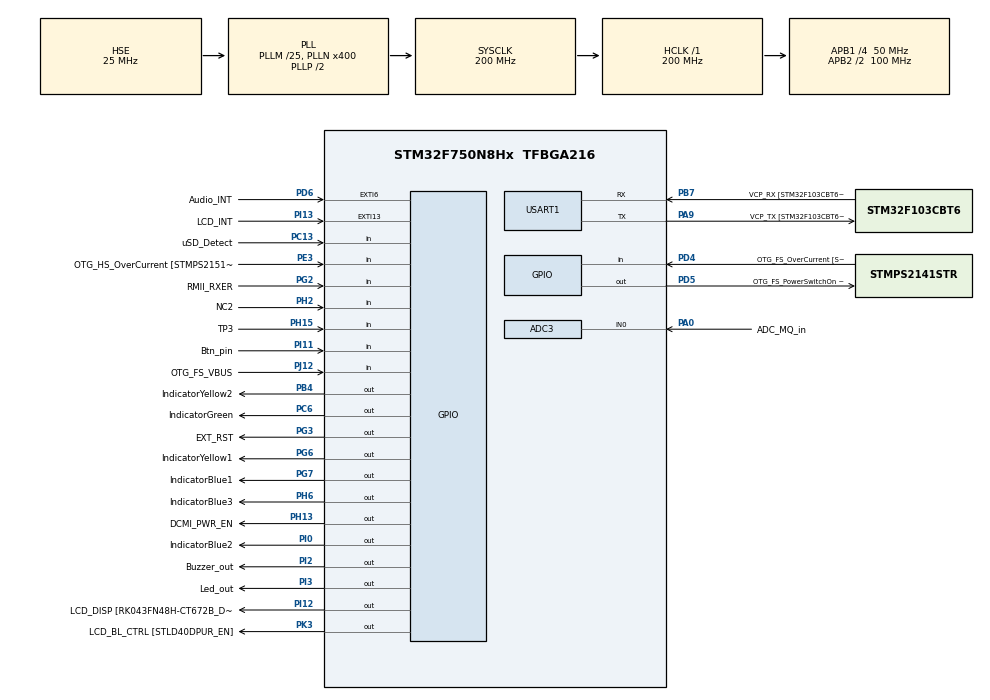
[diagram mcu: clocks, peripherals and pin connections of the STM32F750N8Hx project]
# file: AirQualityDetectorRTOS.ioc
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ADC3.Channel-0\#ChannelRegularConversion=ADC_CHANNEL_0
ADC3.Channel-IN0=ADC_CHANNEL_7
FREERTOS.Mutexes01=RegimeMutex,Dynamic,NULL;LED_Blink_Mutex,Dynamic,NULL;UARTMutex,Dynamic,NULL;LED_FSM_Mutex,Dynamic,NULL;ButtonCountMutex,Dynamic,NULL;SystemWorkStateMutex,Dynamic,NULL
FREERTOS.Tasks01=MainTask,24,1024,StartMainTask,Default,NULL,Dynamic,NULL,NULL;TerminalTask,24,1024,StartTerminalTask,Default,NULL,Dynamic,NULL,NULL;ButtonTask,24,512,StartButtonTask,Default,NULL,Dynamic,NULL,NULL;SingleLEDTask,24,512,StartSingleLEDTask,Default,NULL,Dynamic,NULL,NULL
FREERTOS.Timers01=ButtonTimer,ButtonTimerCallback,osTimerOnce,Default,NULL,Dynamic,NULL
FREERTOS.configTIMER_QUEUE_LENGTH=64
FREERTOS.configTIMER_TASK_PRIORITY=19
FREERTOS.configTIMER_TASK_STACK_DEPTH=1024
FREERTOS.configUSE_NEWLIB_REENTRANT=1
Mcu.Family=STM32F7
Mcu.Name=STM32F750N8Hx
Mcu.Package=TFBGA216
NVIC.PriorityGroup=NVIC_PRIORITYGROUP_4
NVIC.TIM8_TRG_COM_TIM14_IRQn=true\:15\:0\:false\:false\:true\:false\:false\:true\:true
NVIC.TimeBase=TIM8_TRG_COM_TIM14_IRQn
NVIC.TimeBaseIP=TIM14
NVIC.USART1_IRQn=true\:5\:0\:false\:false\:true\:true\:true\:true\:true
PA0/WKUP.GPIO_Label=ADC_MQ_in
PA0/WKUP.GPIO_Mode=GPIO_MODE_ANALOG
PA0/WKUP.GPIO_PuPd=GPIO_NOPULL
PA0/WKUP.Signal=ADCx_IN0
PA1.GPIO_Label=RMII_REF_CLK [LAN8742A-CZ-TR_REFCLK0]
PA1.Signal=ETH_REF_CLK
PA10.GPIO_Label=OTG_FS_ID
PA10.Signal=USB_OTG_FS_ID
PA11.GPIO_Label=OTG_FS_N
PA11.Signal=USB_OTG_FS_DM
PA12.GPIO_Label=OTG_FS_P
PA12.Signal=USB_OTG_FS_DP
PA13.GPIO_Label=SWDIO
PA13.Mode=Serial_Wire
PA13.Signal=SYS_JTMS-SWDIO
PA14.GPIO_Label=SWCLK
PA14.Mode=Serial_Wire
PA14.Signal=SYS_JTCK-SWCLK
PA15.GPIO_Label=ARDUINO PWM/D9
PA15.GPIO_ModeDefaultPP=GPIO_MODE_AF_PP
PA15.GPIO_PuPd=GPIO_NOPULL
PA15.GPIO_Speed=GPIO_SPEED_FREQ_LOW
PA15.Signal=S_TIM2_CH1_ETR
PA2.GPIO_Label=RMII_MDIO [LAN8742A-CZ-TR_MDIO]
PA2.Signal=ETH_MDIO
PA4.GPIO_Label=DCMI_HSYNC
PA4.Signal=DCMI_HSYNC
PA6.Signal=DCMI_PIXCLK
PA7.GPIO_Label=RMII_CRS_DV [LAN8742A-CZ-TR_CRS_DV]
PA7.Signal=ETH_CRS_DV
PA8.GPIO_Label=ARDUINO PWM/D10
PA8.GPIO_ModeDefaultPP=GPIO_MODE_AF_PP
PA8.GPIO_PuPd=GPIO_NOPULL
PA8.GPIO_Speed=GPIO_SPEED_FREQ_LOW
PA8.Signal=S_TIM1_CH1
PA9.GPIO_Label=VCP_TX [STM32F103CBT6_PA3]
PA9.GPIO_PuPd=GPIO_NOPULL
PA9.GPIO_Speed=GPIO_SPEED_FREQ_LOW
PA9.Mode=Asynchronous
PA9.Signal=USART1_TX
PB10.GPIO_Label=ULPI_D3 [USB3320C-EZK_D3]
PB10.Signal=USB_OTG_HS_ULPI_D3
PB14.GPIO_Label=ARDUINO MISO/D12
PB14.GPIO_Mode=GPIO_MODE_AF_PP
PB14.GPIO_PuPd=GPIO_NOPULL
PB14.GPIO_Speed=GPIO_SPEED_FREQ_LOW
PB14.Signal=SPI2_MISO
PB15.GPIO_Label=ARDUINO MOSI/PWM/D11
PB15.GPIO_Mode=GPIO_MODE_AF_PP
PB15.GPIO_PuPd=GPIO_NOPULL
PB15.GPIO_Speed=GPIO_SPEED_FREQ_LOW
PB15.Signal=SPI2_MOSI
PB2.Signal=QUADSPI_CLK
PB3.GPIO_Label=SWO
PB3.Signal=SYS_JTDO-SWO
PB4.GPIO_Label=IndicatorYellow2
PB4.GPIO_PuPd=GPIO_PULLDOWN
PB4.Signal=GPIO_Output
PB6.GPIO_Label=QSPI_NCS [N25Q128A13EF840E_S]
PB6.Signal=QUADSPI_BK1_NCS
PB7.GPIO_Label=VCP_RX [STM32F103CBT6_PA2]
PB7.GPIO_PuPd=GPIO_NOPULL
PB7.GPIO_Speed=GPIO_SPEED_FREQ_LOW
PB7.Mode=Asynchronous
PB7.Signal=USART1_RX
PB8.GPIO_Label=ARDUINO SCL/D15
PB8.GPIO_Mode=GPIO_MODE_AF_OD
PB8.GPIO_Pu=GPIO_PULLUP
PB8.GPIO_Speed=GPIO_SPEED_FREQ_LOW
PB8.Signal=I2C1_SCL
PB9.GPIO_Label=ARDUINO SDA/D14
PB9.GPIO_Mode=GPIO_MODE_AF_OD
PB9.GPIO_Pu=GPIO_PULLUP
PB9.GPIO_Speed=GPIO_SPEED_FREQ_LOW
PB9.Signal=I2C1_SDA
PC1.GPIO_Label=RMII_MDC [LAN8742A-CZ-TR_MDC]
PC1.Signal=ETH_MDC
PC10.GPIO_Label=SDMMC_D2
PC10.Signal=SDMMC1_D2
PC11.GPIO_Label=SDMMC_D3
PC11.Signal=SDMMC1_D3
PC12.GPIO_Label=SDMMC_CK
PC12.Signal=SDMMC1_CK
PC13.GPIO_Label=uSD_Detect
PC13.Signal=GPIO_Input
PC14/OSC32_IN.GPIO_Label=RCC_OSC32_IN
PC14/OSC32_IN.Mode=LSE-External-Oscillator
PC14/OSC32_IN.Signal=RCC_OSC32_IN
PC15/OSC32_OUT.GPIO_Label=RCC_OSC32_OUT
PC15/OSC32_OUT.Mode=LSE-External-Oscillator
PC15/OSC32_OUT.Signal=RCC_OSC32_OUT
PC3.GPIO_Label=FMC_SDCKE0 [MT48LC4M32B2B5-6A_CKE]
PC3.Signal=FMC_SDCKE0
PC4.GPIO_Label=RMII_RXD0 [LAN8742A-CZ-TR_RXD0]
PC4.Signal=ETH_RXD0
PC5.GPIO_Label=RMII_RXD1 [LAN8742A-CZ-TR_RXD1]
PC5.Signal=ETH_RXD1
PC6.GPIO_Label=IndicatorGreen
PC6.GPIO_PuPd=GPIO_PULLDOWN
PC6.Signal=GPIO_Output
PC7.GPIO_Label=ARDUINO RX/D0
PC7.Signal=USART6_RX
PC8.Signal=SDMMC1_D0
PC9.Signal=SDMMC1_D1
PD0.GPIO_Label=FMC_D2 [MT48LC4M32B2B5-6A_DQ2]
PD0.Signal=FMC_D2_DA2
PD1.GPIO_Label=FMC_D3 [MT48LC4M32B2B5-6A_DQ3]
PD1.Signal=FMC_D3_DA3
PD10.GPIO_Label=FMC_D15 [MT48LC4M32B2B5-6A_DQ15]
PD10.Signal=FMC_D15_DA15
PD11.GPIO_Label=QSPI_D0 [N25Q128A13EF840E_DQ0]
PD11.Signal=QUADSPI_BK1_IO0
PD12.GPIO_Label=QSPI_D1 [N25Q128A13EF840E_DQ1]
PD12.Signal=QUADSPI_BK1_IO1
PD13.GPIO_Label=QSPI_D3 [N25Q128A13EF840E_DQ3]
PD13.Signal=QUADSPI_BK1_IO3
PD14.GPIO_Label=FMC_D0 [MT48LC4M32B2B5-6A_DQ0]
PD14.Signal=FMC_D0_DA0
PD15.GPIO_Label=FMC_D1 [MT48LC4M32B2B5-6A_DQ1]
PD15.Signal=FMC_D1_DA1
PD2.GPIO_Label=SDMMC_CMD
PD2.Signal=SDMMC1_CMD
PD3.GPIO_Label=DCMI_D5
PD3.Signal=DCMI_D5
PD4.GPIO_Label=OTG_FS_OverCurrent [STMPS2141STR_Fault]
PD4.Signal=GPIO_Input
PD5.GPIO_Label=OTG_FS_PowerSwitchOn [STMPS2141STR_EN]
PD5.PinState=GPIO_PIN_SET
PD5.Signal=GPIO_Output
PD6.GPIO_Label=Audio_INT
PD6.GPIO_ModeDefaultEXTI=GPIO_MODE_EVT_RISING
PD6.Signal=GPXTI6
PD7.GPIO_Label=SPDIF_RX0 [74LVC1G04SE_4]
PD7.Signal=SPDIFRX_IN0
PD8.GPIO_Label=FMC_D13 [MT48LC4M32B2B5-6A_DQ13]
PD8.Signal=FMC_D13_DA13
PD9.GPIO_Label=FMC_D14 [MT48LC4M32B2B5-6A_DQ14]
PD9.Signal=FMC_D14_DA14
PE0.GPIO_Label=FMC_NBL0 [MT48LC4M32B2B5-6A_DQM0]
PE0.Signal=FMC_NBL0
PE1.GPIO_Label=FMC_NBL1 [MT48LC4M32B2B5-6A_DQM1]
PE1.Signal=FMC_NBL1
PE10.GPIO_Label=FMC_D7 [MT48LC4M32B2B5-6A_DQ7]
PE10.Signal=FMC_D7_DA7
PE11.GPIO_Label=FMC_D8 [MT48LC4M32B2B5-6A_DQ8]
PE11.Signal=FMC_D8_DA8
PE12.GPIO_Label=FMC_D9 [MT48LC4M32B2B5-6A_DQ9]
PE12.Signal=FMC_D9_DA9
PE13.GPIO_Label=FMC_D10 [MT48LC4M32B2B5-6A_DQ10]
PE13.Signal=FMC_D10_DA10
PE14.GPIO_Label=FMC_D11 [MT48LC4M32B2B5-6A_DQ11]
PE14.Signal=FMC_D11_DA11
PE15.GPIO_Label=FMC_D12 [MT48LC4M32B2B5-6A_DQ12]
PE15.Signal=FMC_D12_DA12
PE2.GPIO_Label=QSPI_D2 [N25Q128A13EF840E_DQ2]
PE2.Signal=QUADSPI_BK1_IO2
PE3.GPIO_Label=OTG_HS_OverCurrent [STMPS2151STR_FAULT]
PE3.Signal=GPIO_Input
PE4.GPIO_Label=LCD_B0 [RK043FN48H-CT672B_B0]
PE4.Signal=LTDC_B0
PE5.GPIO_Label=DCMI_D6
PE5.Signal=DCMI_D6
PE6.GPIO_Label=DCMI_D7
PE6.Signal=DCMI_D7
PE7.GPIO_Label=FMC_D4 [MT48LC4M32B2B5-6A_DQ4]
PE7.Signal=FMC_D4_DA4
PE8.GPIO_Label=FMC_D5 [MT48LC4M32B2B5-6A_DQ5]
PE8.Signal=FMC_D5_DA5
PE9.GPIO_Label=FMC_D6 [MT48LC4M32B2B5-6A_DQ6]
PE9.Signal=FMC_D6_DA6
PF0.GPIO_Label=FMC_A0 [MT48LC4M32B2B5-6A_A0]
PF0.Signal=FMC_A0
PF1.GPIO_Label=FMC_A1 [MT48LC4M32B2B5-6A_A1]
PF1.Signal=FMC_A1
PF10.GPIO_Label=ARDUINO A1
PF10.GPIO_Mode=GPIO_MODE_ANALOG
PF10.GPIO_PuPd=GPIO_NOPULL
PF10.Signal=ADC3_IN8
PF11.GPIO_Label=FMC_SDNRAS [MT48LC4M32B2B5-6A_RAS]
PF11.Signal=FMC_SDNRAS
PF12.GPIO_Label=FMC_A6 [MT48LC4M32B2B5-6A_A6]
PF12.Signal=FMC_A6
PF13.GPIO_Label=FMC_A7 [MT48LC4M32B2B5-6A_A7]
PF13.Signal=FMC_A7
PF14.GPIO_Label=FMC_A8 [MT48LC4M32B2B5-6A_A8]
PF14.Signal=FMC_A8
PF15.GPIO_Label=FMC_A9 [MT48LC4M32B2B5-6A_A9]
PF15.Signal=FMC_A9
PF2.GPIO_Label=FMC_A2 [MT48LC4M32B2B5-6A_A2]
PF2.Signal=FMC_A2
PF3.GPIO_Label=FMC_A3 [MT48LC4M32B2B5-6A_A3]
PF3.Signal=FMC_A3
PF4.GPIO_Label=FMC_A4 [MT48LC4M32B2B5-6A_A4]
PF4.Signal=FMC_A4
PF5.GPIO_Label=FMC_A5 [MT48LC4M32B2B5-6A_A5]
PF5.Signal=FMC_A5
PF6.GPIO_Label=ARDUINO A5
PF6.GPIO_Mode=GPIO_MODE_ANALOG
PF6.GPIO_PuPd=GPIO_NOPULL
PF6.Signal=ADC3_IN4
PF7.GPIO_Label=ARDUINO A4
PF7.GPIO_Mode=GPIO_MODE_ANALOG
PF7.GPIO_PuPd=GPIO_NOPULL
PF7.Signal=ADC3_IN5
PF8.GPIO_Label=ARDUINO A3
PF8.GPIO_Mode=GPIO_MODE_ANALOG
PF8.GPIO_PuPd=GPIO_NOPULL
PF8.Signal=ADC3_IN6
PF9.GPIO_Label=ARDUINO A2
PF9.GPIO_Mode=GPIO_MODE_ANALOG
PF9.GPIO_PuPd=GPIO_NOPULL
PF9.Signal=ADC3_IN7
PG0.GPIO_Label=FMC_A10 [MT48LC4M32B2B5-6A_A10]
PG0.Signal=FMC_A10
PG1.GPIO_Label=FMC_A11 [MT48LC4M32B2B5-6A_A11]
PG1.Signal=FMC_A11
PG10.GPIO_Label=SAI2_SDB [WM8994ECS/R_ADCDAT1]
PG10.Signal=SAI2_SD_B
PG11.GPIO_Label=RMII_TX_EN [LAN8742A-CZ-TR_TXEN]
PG11.Signal=ETH_TX_EN
PG12.GPIO_Label=LCD_B4 [RK043FN48H-CT672B_B4]
PG12.Signal=LTDC_B4
PG13.GPIO_Label=RMII_TXD0 [LAN8742A-CZ-TR_TXD0]
PG13.Signal=ETH_TXD0
PG14.GPIO_Label=RMII_TXD1 [LAN8742A-CZ-TR_TXD1]
PG14.Signal=ETH_TXD1
PG15.GPIO_Label=FMC_SDNCAS [MT48LC4M32B2B5-6A_CAS]
PG15.Signal=FMC_SDNCAS
PG2.GPIO_Label=RMII_RXER
PG2.Signal=GPIO_Input
PG3.GPIO_Label=EXT_RST
PG3.Signal=GPIO_Output
PG4.GPIO_Label=FMC_BA0 [MT48LC4M32B2B5-6A_BA0]
PG4.Signal=FMC_A14_BA0
PG5.GPIO_Label=FMC_BA1 [MT48LC4M32B2B5-6A_BA1]
PG5.Signal=FMC_A15_BA1
PG6.GPIO_Label=IndicatorYellow1
PG6.GPIO_PuPd=GPIO_PULLDOWN
PG6.Signal=GPIO_Output
PG7.GPIO_Label=IndicatorBlue1
PG7.GPIO_PuPd=GPIO_PULLDOWN
PG7.Signal=GPIO_Output
PG8.GPIO_Label=FMC_SDCLK [MT48LC4M32B2B5-6A_CLK]
PG8.Signal=FMC_SDCLK
PG9.GPIO_Label=DCMI_VSYNC
PG9.Signal=DCMI_VSYNC
PH0/OSC_IN.GPIO_Label=OSC_25M [NZ2520SB-25.00M_OUT]
PH0/OSC_IN.Mode=HSE-External-Oscillator
PH0/OSC_IN.Signal=RCC_OSC_IN
PH1/OSC_OUT.Mode=HSE-External-Oscillator
PH1/OSC_OUT.Signal=RCC_OSC_OUT
PH10.GPIO_Label=DCMI_D1
PH10.Signal=DCMI_D1
PH11.GPIO_Label=DCMI_D2
PH11.Signal=DCMI_D2
PH12.GPIO_Label=DCMI_D3
PH12.Signal=DCMI_D3
PH13.GPIO_Label=DCMI_PWR_EN
PH13.Signal=GPIO_Output
PH14.GPIO_Label=DCMI_D4
PH14.Signal=DCMI_D4
PH15.GPIO_Label=TP3
PH15.Signal=GPIO_Input
PH2.GPIO_Label=NC2
PH2.Signal=GPIO_Input
PH3.GPIO_Label=FMC_SDNE0 [MT48LC4M32B2B5-6A_CS]
PH3.Signal=FMC_SDNE0
PH5.GPIO_Label=FMC_SDNME [MT48LC4M32B2B5-6A_WE]
PH5.Signal=FMC_SDNWE
PH6.GPIO_Label=IndicatorBlue3
PH6.GPIO_PuPd=GPIO_PULLDOWN
PH6.Signal=GPIO_Output
PH7.GPIO_Label=LCD_SCL [RK043FN48H-CT672B_SCL]
PH7.GPIO_Pu=GPIO_PULLUP
PH7.Signal=I2C3_SCL
PH8.GPIO_Label=LCD_SDA [RK043FN48H-CT672B_SDA]
PH8.GPIO_Pu=GPIO_PULLUP
PH8.Signal=I2C3_SDA
PH9.GPIO_Label=DCMI_D0
PH9.Signal=DCMI_D0
PI0.GPIO_Label=IndicatorBlue2
PI0.GPIO_PuPd=GPIO_PULLDOWN
PI0.Signal=GPIO_Output
PI1.GPIO_Label=ARDUINO SCK/D13
PI1.GPIO_Mode=GPIO_MODE_AF_PP
PI1.GPIO_PuPd=GPIO_NOPULL
PI1.GPIO_Speed=GPIO_SPEED_FREQ_LOW
PI1.Signal=SPI2_SCK
PI10.GPIO_Label=LCD_HSYNC [RK043FN48H-CT672B_HSYNC]
PI10.Signal=LTDC_HSYNC
PI11.GPIO_Label=Btn_pin
PI11.GPIO_PuPd=GPIO_PULLDOWN
PI11.Signal=GPIO_Input
PI12.GPIO_Label=LCD_DISP [RK043FN48H-CT672B_DISP] 
PI12.PinState=GPIO_PIN_SET
PI12.Signal=GPIO_Output
PI13.GPIO_Label=LCD_INT
PI13.GPIO_ModeDefaultEXTI=GPIO_MODE_EVT_RISING
PI13.Signal=GPXTI13
PI14.GPIO_Label=LCD_CLK [RK043FN48H-CT672B_CLK]
PI14.Signal=LTDC_CLK
PI15.GPIO_Label=LCD_R0 [RK043FN48H-CT672B_R0]
PI15.Signal=LTDC_R0
PI2.GPIO_Label=Buzzer_out
PI2.GPIO_PuPd=GPIO_PULLDOWN
PI2.Signal=GPIO_Output
PI3.GPIO_Label=Led_out
PI3.GPIO_PuPd=GPIO_PULLDOWN
PI3.Signal=GPIO_Output
PI4.GPIO_Label=SAI2_MCLKA [WM8994ECS/R_MCLK1]
PI4.Signal=SAI2_MCLK_A
PI5.GPIO_Label=SAI2_SCKA [WM8994ECS/R_BCLK1]
PI5.Signal=SAI2_SCK_A
PI6.GPIO_Label=SAI2_SDA [WM8994ECS/R_DACDAT1]
PI6.Signal=SAI2_SD_A
PI7.GPIO_Label=SAI2_FSA [WM8994ECS/R_LRCLK1]
PI7.Signal=SAI2_FS_A
PI8.GPIO_Label=NC1 [TP2]
PI8.Signal=RTC_TS
PI9.GPIO_Label=LCD_VSYNC [RK043FN48H-CT672B_VSYNC]
PI9.Signal=LTDC_VSYNC
PJ0.GPIO_Label=LCD_R1 [RK043FN48H-CT672B_R1]
PJ0.Signal=LTDC_R1
PJ1.GPIO_Label=LCD_R2 [RK043FN48H-CT672B_R2]
PJ1.Signal=LTDC_R2
PJ10.GPIO_Label=LCD_G3 [RK043FN48H-CT672B_G3]
PJ10.Signal=LTDC_G3
PJ11.GPIO_Label=LCD_G4 [RK043FN48H-CT672B_G4]
PJ11.Signal=LTDC_G4
PJ12.GPIO_Label=OTG_FS_VBUS
PJ12.Signal=GPIO_Input
PJ13.GPIO_Label=LCD_B1 [RK043FN48H-CT672B_B1]
PJ13.Signal=LTDC_B1
PJ14.GPIO_Label=LCD_B2 [RK043FN48H-CT672B_B2]
PJ14.Signal=LTDC_B2
PJ15.GPIO_Label=LCD_B3 [RK043FN48H-CT672B_B3]
PJ15.Signal=LTDC_B3
PJ2.GPIO_Label=LCD_R3 [RK043FN48H-CT672B_R3]
PJ2.Signal=LTDC_R3
PJ3.GPIO_Label=LCD_R4 [RK043FN48H-CT672B_R4]
PJ3.Signal=LTDC_R4
PJ4.GPIO_Label=LCD_R5 [RK043FN48H-CT672B_R5]
PJ4.Signal=LTDC_R5
PJ5.GPIO_Label=LCD_R6 [RK043FN48H-CT672B_R6]
PJ5.Signal=LTDC_R6
PJ6.GPIO_Label=LCD_R7 [RK043FN48H-CT672B_R7]
PJ6.Signal=LTDC_R7
PJ7.GPIO_Label=LCD_G0 [RK043FN48H-CT672B_G0]
PJ7.Signal=LTDC_G0
PJ8.GPIO_Label=LCD_G1 [RK043FN48H-CT672B_G1]
PJ8.Signal=LTDC_G1
PJ9.GPIO_Label=LCD_G2 [RK043FN48H-CT672B_G2]
PJ9.Signal=LTDC_G2
PK0.GPIO_Label=LCD_G5 [RK043FN48H-CT672B_G5]
PK0.Signal=LTDC_G5
PK1.GPIO_Label=LCD_G6 [RK043FN48H-CT672B_G6]
PK1.Signal=LTDC_G6
PK2.GPIO_Label=LCD_G7 [RK043FN48H-CT672B_G7]
PK2.Signal=LTDC_G7
PK3.GPIO_Label=LCD_BL_CTRL [STLD40DPUR_EN]
PK3.GPIO_Speed=GPIO_SPEED_FREQ_LOW
PK3.PinState=GPIO_PIN_SET
PK3.Signal=GPIO_Output
PK4.GPIO_Label=LCD_B5 [RK043FN48H-CT672B_B5]
PK4.Signal=LTDC_B5
PK5.GPIO_Label=LCD_B6 [RK043FN48H-CT672B_B6]
PK5.Signal=LTDC_B6
PK6.GPIO_Label=LCD_B7 [RK043FN48H-CT672B_B7]
PK6.Signal=LTDC_B7
PK7.GPIO_Label=LCD_DE [RK043FN48H-CT672B_DE]
PK7.Signal=LTDC_DE
ProjectManager.HeapSize=0x200
ProjectManager.StackSize=0x400
ProjectManager.TargetToolchain=STM32CubeIDE
RCC.AHBFreq_Value=200000000
RCC.APB1CLKDivider=RCC_HCLK_DIV4
RCC.APB1Freq_Value=50000000
RCC.APB1TimFreq_Value=100000000
RCC.APB2CLKDivider=RCC_HCLK_DIV2
RCC.APB2Freq_Value=100000000
RCC.APB2TimFreq_Value=200000000
RCC.CortexFreq_Value=200000000
RCC.HCLKFreq_Value=200000000
RCC.HSE_VALUE=25000000
RCC.HSI_VALUE=16000000
RCC.PLL48CLockSelection=RCC_CLK48SOURCE_PLLSAIP
RCC.PLLI2SN=100
RCC.PLLM=25
RCC.PLLN=400
RCC.PLLQ=9
RCC.PLLSAIN=384
RCC.PLLSAIP=RCC_PLLSAIP_DIV8
RCC.PLLSAIR=5
RCC.PLLSourceVirtual=RCC_PLLSOURCE_HSE
RCC.SDMMCClockSelection=RCC_SDMMC1CLKSOURCE_CLK48
RCC.SYSCLKFreq_VALUE=200000000
RCC.SYSCLKSource=RCC_SYSCLKSOURCE_PLLCLK
RCC.USBFreq_Value=48000000
RCC.VCOOutputFreq_Value=400000000
SH.ADCx_IN0.0=ADC3_IN0,IN0
SH.FMC_A0.0=FMC_A0
SH.FMC_A1.0=FMC_A1
SH.FMC_A10.0=FMC_A10
SH.FMC_A11.0=FMC_A11
SH.FMC_A14_BA0.0=FMC_BA0
SH.FMC_A15_BA1.0=FMC_BA1
SH.FMC_A2.0=FMC_A2
SH.FMC_A3.0=FMC_A3
SH.FMC_A4.0=FMC_A4
SH.FMC_A5.0=FMC_A5
SH.FMC_A6.0=FMC_A6
SH.FMC_A7.0=FMC_A7
SH.FMC_A8.0=FMC_A8
SH.FMC_A9.0=FMC_A9
SH.FMC_D0_DA0.0=FMC_D0
SH.FMC_D10_DA10.0=FMC_D10
SH.FMC_D11_DA11.0=FMC_D11
SH.FMC_D12_DA12.0=FMC_D12
SH.FMC_D13_DA13.0=FMC_D13
SH.FMC_D14_DA14.0=FMC_D14
SH.FMC_D15_DA15.0=FMC_D15
SH.FMC_D1_DA1.0=FMC_D1
SH.FMC_D2_DA2.0=FMC_D2
SH.FMC_D3_DA3.0=FMC_D3
SH.FMC_D4_DA4.0=FMC_D4
SH.FMC_D5_DA5.0=FMC_D5
SH.FMC_D6_DA6.0=FMC_D6
SH.FMC_D7_DA7.0=FMC_D7
SH.FMC_D8_DA8.0=FMC_D8
SH.FMC_D9_DA9.0=FMC_D9
SH.FMC_NBL0.0=FMC_NBL0
SH.FMC_NBL1.0=FMC_NBL1
SH.FMC_SDCLK.0=FMC_SDCLK
SH.FMC_SDNCAS.0=FMC_SDNCAS
SH.FMC_SDNRAS.0=FMC_SDNRAS
SH.FMC_SDNWE.0=FMC_SDNWE
SH.S_TIM1_CH1.0=TIM1_CH1
SH.S_TIM2_CH1_ETR.0=TIM2_CH1
USART1.VirtualMode-Asynchronous=VM_ASYNC
VP_CRC_VS_CRC.Mode=CRC_Activate
VP_FREERTOS_VS_CMSIS_V2.Mode=CMSIS_V2
VP_SYS_VS_tim14.Mode=TIM14
board=STM32F7508-DK

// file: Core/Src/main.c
/* USER CODE BEGIN Header */
/**
  ******************************************************************************
  * @file           : main.c
  * @brief          : Main program body
  ******************************************************************************
  * @attention
  *
  * Copyright (c) 2024 STMicroelectronics.
  * All rights reserved.
  *
  * This software is licensed under terms that can be found in the LICENSE file
  * in the root directory of this software component.
  * If no LICENSE file comes with this software, it is provided AS-IS.
  *
  ******************************************************************************
  */
/* USER CODE END Header */
#include "main.h"
#include "cmsis_os.h"

/* USER CODE BEGIN Includes */

#include "Variables.h"

/* USER CODE END Includes */

/* USER CODE BEGIN PD */
#define DangerousPPM 2000 // to be adjusted
/* USER CODE END PD */

ADC_HandleTypeDef hadc3;

CRC_HandleTypeDef hcrc;

UART_HandleTypeDef huart1;

/* Definitions for MainTask */
osThreadId_t MainTaskHandle;
const osThreadAttr_t MainTask_attributes = {
  .name = "MainTask",
  .stack_size = 1024 * 4,
  .priority = (osPriority_t) osPriorityNormal,
};
/* Definitions for TerminalTask */
osThreadId_t TerminalTaskHandle;
const osThreadAttr_t TerminalTask_attributes = {
  .name = "TerminalTask",
  .stack_size = 1024 * 4,
  .priority = (osPriority_t) osPriorityNormal,
};
/* Definitions for ButtonTask */
osThreadId_t ButtonTaskHandle;
const osThreadAttr_t ButtonTask_attributes = {
  .name = "ButtonTask",
  .stack_size = 512 * 4,
  .priority = (osPriority_t) osPriorityNormal,
};
/* Definitions for SingleLEDTask */
osThreadId_t SingleLEDTaskHandle;
const osThreadAttr_t SingleLEDTask_attributes = {
  .name = "SingleLEDTask",
  .stack_size = 512 * 4,
  .priority = (osPriority_t) osPriorityNormal,
};
/* Definitions for ButtonTimer */
osTimerId_t ButtonTimerHandle;
const osTimerAttr_t ButtonTimer_attributes = {
  .name = "ButtonTimer"
};
/* Definitions for RegimeMutex */
osMutexId_t RegimeMutexHandle;
const osMutexAttr_t RegimeMutex_attributes = {
  .name = "RegimeMutex"
};
/* Definitions for LED_Blink_Mutex */
osMutexId_t LED_Blink_MutexHandle;
const osMutexAttr_t LED_Blink_Mutex_attributes = {
  .name = "LED_Blink_Mutex"
};
/* Definitions for UARTMutex */
osMutexId_t UARTMutexHandle;
const osMutexAttr_t UARTMutex_attributes = {
  .name = "UARTMutex"
};
/* Definitions for LED_FSM_Mutex */
osMutexId_t LED_FSM_MutexHandle;
const osMutexAttr_t LED_FSM_Mutex_attributes = {
  .name = "LED_FSM_Mutex"
};
/* Definitions for ButtonCountMutex */
osMutexId_t ButtonCountMutexHandle;
const osMutexAttr_t ButtonCountMutex_attributes = {
  .name = "ButtonCountMutex"
};
/* Definitions for SystemWorkStateMutex */
osMutexId_t SystemWorkStateMutexHandle;
const osMutexAttr_t SystemWorkStateMutex_attributes = {
  .name = "SystemWorkStateMutex"
};

void SystemClock_Config(void);
static void MX_GPIO_Init(void);
static void MX_ADC3_Init(void);
static void MX_CRC_Init(void);
static void MX_USART1_UART_Init(void);
void StartMainTask(void *argument);
void StartTerminalTask(void *argument);
void StartButtonTask(void *argument);
void StartSingleLEDTask(void *argument);
void ButtonTimerCallback(void *argument);

/* USER CODE BEGIN PFP */

// Button variables //
volatile uint8_t button_press_counter = 0;
// END Button variables //

// Read parameters variables //
volatile bool quality_status = true;
// END Read parameters variables //

// For UART commands //
uint16_t cmd_find = 0;
const uint16_t len_of_array = 20;
// END For UART commands //

//Messages for sending
static char IdleMSG[] = "System waits for configuration";
static char PPM_MSG[] = "PPM = ";
static char AlertMSG[] = "Dangerous leves of PPM in the room";
static char RoomClearedMSG[] = "Room cleared, it is now safe to return";
static char S1WorkStateMSG[] = "S1 work regime selected";
static char S3WorkStateMSG[] = "S3 work regime selected";
static char S5WorkStateMSG[] = "S5 work regime selected";
static char FAN_ON[] = "FAN started";
static char FAN_OFF[] = "FAN stoped";
static char ErrorMSG[] = "Unknown command, type HELP to see all commands";

// Structs //

char* cmdStrings[] = {

		"IDLE\r",			 // cmd_0
		"WORK_S1\r",	 	 // cmd_1
		"WORK_S3\r",		 // cmd_2
		"WORK_S5\r",		 // cmd_3

		"READ_MQ_SENSOR\r",	 // cmd_4

		"SEND_MQ_DATA\r",	 // cmd_5

		"FAN_ON\r",		     // cmd_6
		"FAN_OFF\r",		 // cmd_7

		"ALARM_ON\r",	   	 // cmd_8
		"ALARM_OFF\r",  	 // cmd_9

		"LED_ON\r",		     // cmd_10
		"LED_OFF\r",		 // cmd_11

		"SEGMENT_0\r",		 // cmd_12
		"SEGMENT_1\r",		 // cmd_13
		"SEGMENT_2\r",	   	 // cmd_14
		"SEGMENT_3\r",		 // cmd_15
		"SEGMENT_4\r",		 // cmd_16
		"SEGMENT_5\r",		 // cmd_17
		"SEGMENT_6\r", 		 // cmd_18

		"HELP\r", 	 		 // cmd_19

};

// FSMs //
ProgramStateFSM progState = P_IDLE_START;
ProgramChangeStateFSM  progChangeState = PC_IDLE;
LED_StatusFSM ledState = LED_OFF;
UART_commandsFSM uartCmdState;

/* USER CODE END PFP */

int main(void)
{

  /* MCU Configuration--------------------------------------------------------*/

  /* Reset of all peripherals, Initializes the Flash interface and the Systick. */
  HAL_Init();

  /* Configure the system clock */
  SystemClock_Config();

  /* Initialize all configured peripherals */
  MX_GPIO_Init();
  MX_ADC3_Init();
  MX_CRC_Init();
  MX_USART1_UART_Init();
  /* USER CODE BEGIN 2 */

  DevicesInit(); // Function that initializes all of systems components
//  LED_Drive(true);
//  osTimerStop(ButtonTimerHandle);
//  osTimerStart(LEDTimerHandle, 3000);

  /* USER CODE END 2 */

  /* Init scheduler */
  osKernelInitialize();
  /* Create the mutex(es) */
  /* creation of RegimeMutex */
  RegimeMutexHandle = osMutexNew(&RegimeMutex_attributes);

  /* creation of LED_Blink_Mutex */
  LED_Blink_MutexHandle = osMutexNew(&LED_Blink_Mutex_attributes);

  /* creation of UARTMutex */
  UARTMutexHandle = osMutexNew(&UARTMutex_attributes);

  /* creation of LED_FSM_Mutex */
  LED_FSM_MutexHandle = osMutexNew(&LED_FSM_Mutex_attributes);

  /* creation of ButtonCountMutex */
  ButtonCountMutexHandle = osMutexNew(&ButtonCountMutex_attributes);

  /* creation of SystemWorkStateMutex */
  SystemWorkStateMutexHandle = osMutexNew(&SystemWorkStateMutex_attributes);

  /* Create the timer(s) */
  /* creation of ButtonTimer */
  ButtonTimerHandle = osTimerNew(ButtonTimerCallback, osTimerOnce, NULL, &ButtonTimer_attributes);

  /* Create the thread(s) */
  /* creation of MainTask */
  MainTaskHandle = osThreadNew(StartMainTask, NULL, &MainTask_attributes);

  /* creation of TerminalTask */
  TerminalTaskHandle = osThreadNew(StartTerminalTask, NULL, &TerminalTask_attributes);

  /* creation of ButtonTask */
  ButtonTaskHandle = osThreadNew(StartButtonTask, NULL, &ButtonTask_attributes);

  /* creation of SingleLEDTask */
  SingleLEDTaskHandle = osThreadNew(StartSingleLEDTask, NULL, &SingleLEDTask_attributes);

  /* Start scheduler */
  osKernelStart();

  /* We should never get here as control is now taken by the scheduler */

  /* Infinite loop */
  while (1)
  {

  }
}

void SystemClock_Config(void)
{
  RCC_OscInitTypeDef RCC_OscInitStruct = {0};
  RCC_ClkInitTypeDef RCC_ClkInitStruct = {0};

  /** Configure LSE Drive Capability
  */
  HAL_PWR_EnableBkUpAccess();

  /** Configure the main internal regulator output voltage
  */
  __HAL_RCC_PWR_CLK_ENABLE();
  __HAL_PWR_VOLTAGESCALING_CONFIG(PWR_REGULATOR_VOLTAGE_SCALE1);

  /** Initializes the RCC Oscillators according to the specified parameters
  * in the RCC_OscInitTypeDef structure.
  */
  RCC_OscInitStruct.OscillatorType = RCC_OSCILLATORTYPE_HSE;
  RCC_OscInitStruct.HSEState = RCC_HSE_ON;
  RCC_OscInitStruct.PLL.PLLState = RCC_PLL_ON;
  RCC_OscInitStruct.PLL.PLLSource = RCC_PLLSOURCE_HSE;
  RCC_OscInitStruct.PLL.PLLM = 25;
  RCC_OscInitStruct.PLL.PLLN = 400;
  RCC_OscInitStruct.PLL.PLLP = RCC_PLLP_DIV2;
  RCC_OscInitStruct.PLL.PLLQ = 9;
  if (HAL_RCC_OscConfig(&RCC_OscInitStruct) != HAL_OK)
  {
    Error_Handler();
  }

  /** Activate the Over-Drive mode
  */
  if (HAL_PWREx_EnableOverDrive() != HAL_OK)
  {
    Error_Handler();
  }

  /** Initializes the CPU, AHB and APB buses clocks
  */
  RCC_ClkInitStruct.ClockType = RCC_CLOCKTYPE_HCLK|RCC_CLOCKTYPE_SYSCLK
                              |RCC_CLOCKTYPE_PCLK1|RCC_CLOCKTYPE_PCLK2;
  RCC_ClkInitStruct.SYSCLKSource = RCC_SYSCLKSOURCE_PLLCLK;
  RCC_ClkInitStruct.AHBCLKDivider = RCC_SYSCLK_DIV1;
  RCC_ClkInitStruct.APB1CLKDivider = RCC_HCLK_DIV4;
  RCC_ClkInitStruct.APB2CLKDivider = RCC_HCLK_DIV2;

  if (HAL_RCC_ClockConfig(&RCC_ClkInitStruct, FLASH_LATENCY_6) != HAL_OK)
  {
    Error_Handler();
  }
}

static void MX_ADC3_Init(void)
{

  ADC_ChannelConfTypeDef sConfig = {0};

  /** Configure the global features of the ADC (Clock, Resolution, Data Alignment and number of conversion)
  */
  hadc3.Instance = ADC3;
  hadc3.Init.ClockPrescaler = ADC_CLOCK_SYNC_PCLK_DIV4;
  hadc3.Init.Resolution = ADC_RESOLUTION_12B;
  hadc3.Init.ScanConvMode = ADC_SCAN_DISABLE;
  hadc3.Init.ContinuousConvMode = DISABLE;
  hadc3.Init.DiscontinuousConvMode = DISABLE;
  hadc3.Init.ExternalTrigConvEdge = ADC_EXTERNALTRIGCONVEDGE_NONE;
  hadc3.Init.ExternalTrigConv = ADC_SOFTWARE_START;
  hadc3.Init.DataAlign = ADC_DATAALIGN_RIGHT;
  hadc3.Init.NbrOfConversion = 1;
  hadc3.Init.DMAContinuousRequests = DISABLE;
  hadc3.Init.EOCSelection = ADC_EOC_SINGLE_CONV;
  if (HAL_ADC_Init(&hadc3) != HAL_OK)
  {
    Error_Handler();
  }

  /** Configure for the selected ADC regular channel its corresponding rank in the sequencer and its sample time.
  */
  sConfig.Channel = ADC_CHANNEL_0;
  sConfig.Rank = ADC_REGULAR_RANK_1;
  sConfig.SamplingTime = ADC_SAMPLETIME_3CYCLES;
  if (HAL_ADC_ConfigChannel(&hadc3, &sConfig) != HAL_OK)
  {
    Error_Handler();
  }

}

static void MX_CRC_Init(void)
{

  hcrc.Instance = CRC;
  hcrc.Init.DefaultPolynomialUse = DEFAULT_POLYNOMIAL_ENABLE;
  hcrc.Init.DefaultInitValueUse = DEFAULT_INIT_VALUE_ENABLE;
  hcrc.Init.InputDataInversionMode = CRC_INPUTDATA_INVERSION_NONE;
  hcrc.Init.OutputDataInversionMode = CRC_OUTPUTDATA_INVERSION_DISABLE;
  hcrc.InputDataFormat = CRC_INPUTDATA_FORMAT_BYTES;
  if (HAL_CRC_Init(&hcrc) != HAL_OK)
  {
    Error_Handler();
  }

}

static void MX_USART1_UART_Init(void)
{

  huart1.Instance = USART1;
  huart1.Init.BaudRate = 115200;
  huart1.Init.WordLength = UART_WORDLENGTH_8B;
  huart1.Init.StopBits = UART_STOPBITS_1;
  huart1.Init.Parity = UART_PARITY_NONE;
  huart1.Init.Mode = UART_MODE_TX_RX;
  huart1.Init.HwFlowCtl = UART_HWCONTROL_NONE;
  huart1.Init.OverSampling = UART_OVERSAMPLING_16;
  huart1.Init.OneBitSampling = UART_ONE_BIT_SAMPLE_DISABLE;
  huart1.AdvancedInit.AdvFeatureInit = UART_ADVFEATURE_NO_INIT;
  if (HAL_UART_Init(&huart1) != HAL_OK)
  {
    Error_Handler();
  }

}

static void MX_GPIO_Init(void)
{
  GPIO_InitTypeDef GPIO_InitStruct = {0};

  /* GPIO Ports Clock Enable */
  __HAL_RCC_GPIOE_CLK_ENABLE();
  __HAL_RCC_GPIOG_CLK_ENABLE();
  __HAL_RCC_GPIOB_CLK_ENABLE();
  __HAL_RCC_GPIOD_CLK_ENABLE();
  __HAL_RCC_GPIOC_CLK_ENABLE();
  __HAL_RCC_GPIOA_CLK_ENABLE();
  __HAL_RCC_GPIOJ_CLK_ENABLE();
  __HAL_RCC_GPIOI_CLK_ENABLE();
  __HAL_RCC_GPIOK_CLK_ENABLE();
  __HAL_RCC_GPIOF_CLK_ENABLE();
  __HAL_RCC_GPIOH_CLK_ENABLE();

  /*Configure GPIO pin Output Level */
  HAL_GPIO_WritePin(IndicatorYellow2_GPIO_Port, IndicatorYellow2_Pin, GPIO_PIN_RESET);

  /*Configure GPIO pin Output Level */
  HAL_GPIO_WritePin(OTG_FS_PowerSwitchOn_GPIO_Port, OTG_FS_PowerSwitchOn_Pin, GPIO_PIN_SET);

  /*Configure GPIO pin Output Level */
  HAL_GPIO_WritePin(GPIOI, Led_out_Pin|Buzzer_out_Pin|IndicatorBlue2_Pin, GPIO_PIN_RESET);

  /*Configure GPIO pin Output Level */
  HAL_GPIO_WritePin(LCD_BL_CTRL_GPIO_Port, LCD_BL_CTRL_Pin, GPIO_PIN_SET);

  /*Configure GPIO pin Output Level */
  HAL_GPIO_WritePin(LCD_DISP_GPIO_Port, LCD_DISP_Pin, GPIO_PIN_SET);

  /*Configure GPIO pin Output Level */
  HAL_GPIO_WritePin(GPIOH, DCMI_PWR_EN_Pin|IndicatorBlue3_Pin, GPIO_PIN_RESET);

  /*Configure GPIO pin Output Level */
  HAL_GPIO_WritePin(IndicatorGreen_GPIO_Port, IndicatorGreen_Pin, GPIO_PIN_RESET);

  /*Configure GPIO pin Output Level */
  HAL_GPIO_WritePin(GPIOG, IndicatorBlue1_Pin|IndicatorYellow1_Pin|EXT_RST_Pin, GPIO_PIN_RESET);

  /*Configure GPIO pin : LCD_B0_Pin */
  GPIO_InitStruct.Pin = LCD_B0_Pin;
  GPIO_InitStruct.Mode = GPIO_MODE_AF_PP;
  GPIO_InitStruct.Pull = GPIO_NOPULL;
  GPIO_InitStruct.Speed = GPIO_SPEED_FREQ_LOW;
  GPIO_InitStruct.Alternate = GPIO_AF14_LTDC;
  HAL_GPIO_Init(LCD_B0_GPIO_Port, &GPIO_InitStruct);

  /*Configure GPIO pin : OTG_HS_OverCurrent_Pin */
  GPIO_InitStruct.Pin = OTG_HS_OverCurrent_Pin;
  GPIO_InitStruct.Mode = GPIO_MODE_INPUT;
  GPIO_InitStruct.Pull = GPIO_NOPULL;
  HAL_GPIO_Init(OTG_HS_OverCurrent_GPIO_Port, &GPIO_InitStruct);

  /*Configure GPIO pin : QSPI_D2_Pin */
  GPIO_InitStruct.Pin = QSPI_D2_Pin;
  GPIO_InitStruct.Mode = GPIO_MODE_AF_PP;
  GPIO_InitStruct.Pull = GPIO_NOPULL;
  GPIO_InitStruct.Speed = GPIO_SPEED_FREQ_VERY_HIGH;
  GPIO_InitStruct.Alternate = GPIO_AF9_QUADSPI;
  HAL_GPIO_Init(QSPI_D2_GPIO_Port, &GPIO_InitStruct);

  /*Configure GPIO pins : RMII_TXD1_Pin RMII_TXD0_Pin RMII_TX_EN_Pin */
  GPIO_InitStruct.Pin = RMII_TXD1_Pin|RMII_TXD0_Pin|RMII_TX_EN_Pin;
  GPIO_InitStruct.Mode = GPIO_MODE_AF_PP;
  GPIO_InitStruct.Pull = GPIO_NOPULL;
  GPIO_InitStruct.Speed = GPIO_SPEED_FREQ_VERY_HIGH;
  GPIO_InitStruct.Alternate = GPIO_AF11_ETH;
  HAL_GPIO_Init(GPIOG, &GPIO_InitStruct);

  /*Configure GPIO pins : FMC_NBL1_Pin FMC_NBL0_Pin FMC_D5_Pin FMC_D6_Pin
                           FMC_D8_Pin FMC_D11_Pin FMC_D4_Pin FMC_D7_Pin
                           FMC_D9_Pin FMC_D12_Pin FMC_D10_Pin */
  GPIO_InitStruct.Pin = FMC_NBL1_Pin|FMC_NBL0_Pin|FMC_D5_Pin|FMC_D6_Pin
                          |FMC_D8_Pin|FMC_D11_Pin|FMC_D4_Pin|FMC_D7_Pin
                          |FMC_D9_Pin|FMC_D12_Pin|FMC_D10_Pin;
  GPIO_InitStruct.Mode = GPIO_MODE_AF_PP;
  GPIO_InitStruct.Pull = GPIO_NOPULL;
  GPIO_InitStruct.Speed = GPIO_SPEED_FREQ_VERY_HIGH;
  GPIO_InitStruct.Alternate = GPIO_AF12_FMC;
  HAL_GPIO_Init(GPIOE, &GPIO_InitStruct);

  /*Configure GPIO pins : ARDUINO_SCL_D15_Pin ARDUINO_SDA_D14_Pin */
  GPIO_InitStruct.Pin = ARDUINO_SCL_D15_Pin|ARDUINO_SDA_D14_Pin;
  GPIO_InitStruct.Mode = GPIO_MODE_AF_OD;
  GPIO_InitStruct.Pull = GPIO_PULLUP;
  GPIO_InitStruct.Speed = GPIO_SPEED_FREQ_LOW;
  GPIO_InitStruct.Alternate = GPIO_AF4_I2C1;
  HAL_GPIO_Init(GPIOB, &GPIO_InitStruct);

  /*Configure GPIO pin : IndicatorYellow2_Pin */
  GPIO_InitStruct.Pin = IndicatorYellow2_Pin;
  GPIO_InitStruct.Mode = GPIO_MODE_OUTPUT_PP;
  GPIO_InitStruct.Pull = GPIO_PULLDOWN;
  GPIO_InitStruct.Speed = GPIO_SPEED_FREQ_LOW;
  HAL_GPIO_Init(IndicatorYellow2_GPIO_Port, &GPIO_InitStruct);

  /*Configure GPIO pin : SPDIF_RX0_Pin */
  GPIO_InitStruct.Pin = SPDIF_RX0_Pin;
  GPIO_InitStruct.Mode = GPIO_MODE_AF_PP;
  GPIO_InitStruct.Pull = GPIO_NOPULL;
  GPIO_InitStruct.Speed = GPIO_SPEED_FREQ_LOW;
  GPIO_InitStruct.Alternate = GPIO_AF8_SPDIFRX;
  HAL_GPIO_Init(SPDIF_RX0_GPIO_Port, &GPIO_InitStruct);

  /*Configure GPIO pins : SDMMC_CK_Pin SDMMC_D3_Pin SDMMC_D2_Pin PC9
                           PC8 */
  GPIO_InitStruct.Pin = SDMMC_CK_Pin|SDMMC_D3_Pin|SDMMC_D2_Pin|GPIO_PIN_9
                          |GPIO_PIN_8;
  GPIO_InitStruct.Mode = GPIO_MODE_AF_PP;
  GPIO_InitStruct.Pull = GPIO_NOPULL;
  GPIO_InitStruct.Speed = GPIO_SPEED_FREQ_VERY_HIGH;
  GPIO_InitStruct.Alternate = GPIO_AF12_SDMMC1;
  HAL_GPIO_Init(GPIOC, &GPIO_InitStruct);

  /*Configure GPIO pin : ARDUINO_PWM_D9_Pin */
  GPIO_InitStruct.Pin = ARDUINO_PWM_D9_Pin;
  GPIO_InitStruct.Mode = GPIO_MODE_AF_PP;
  GPIO_InitStruct.Pull = GPIO_NOPULL;
  GPIO_InitStruct.Speed = GPIO_SPEED_FREQ_LOW;
  GPIO_InitStruct.Alternate = GPIO_AF1_TIM2;
  HAL_GPIO_Init(ARDUINO_PWM_D9_GPIO_Port, &GPIO_InitStruct);

  /*Configure GPIO pins : DCMI_D6_Pin DCMI_D7_Pin */
  GPIO_InitStruct.Pin = DCMI_D6_Pin|DCMI_D7_Pin;
  GPIO_InitStruct.Mode = GPIO_MODE_AF_PP;
  GPIO_InitStruct.Pull = GPIO_NOPULL;
  GPIO_InitStruct.Speed = GPIO_SPEED_FREQ_LOW;
  GPIO_InitStruct.Alternate = GPIO_AF13_DCMI;
  HAL_GPIO_Init(GPIOE, &GPIO_InitStruct);

  /*Configure GPIO pin : QSPI_NCS_Pin */
  GPIO_InitStruct.Pin = QSPI_NCS_Pin;
  GPIO_InitStruct.Mode = GPIO_MODE_AF_PP;
  GPIO_InitStruct.Pull = GPIO_NOPULL;
  GPIO_InitStruct.Speed = GPIO_SPEED_FREQ_VERY_HIGH;
  GPIO_InitStruct.Alternate = GPIO_AF10_QUADSPI;
  HAL_GPIO_Init(QSPI_NCS_GPIO_Port, &GPIO_InitStruct);

  /*Configure GPIO pins : FMC_SDNCAS_Pin FMC_SDCLK_Pin FMC_A11_Pin FMC_A10_Pin
                           FMC_BA1_Pin FMC_BA0_Pin */
  GPIO_InitStruct.Pin = FMC_SDNCAS_Pin|FMC_SDCLK_Pin|FMC_A11_Pin|FMC_A10_Pin
                          |FMC_BA1_Pin|FMC_BA0_Pin;
  GPIO_InitStruct.Mode = GPIO_MODE_AF_PP;
  GPIO_InitStruct.Pull = GPIO_NOPULL;
  GPIO_InitStruct.Speed = GPIO_SPEED_FREQ_VERY_HIGH;
  GPIO_InitStruct.Alternate = GPIO_AF12_FMC;
  HAL_GPIO_Init(GPIOG, &GPIO_InitStruct);

  /*Configure GPIO pins : LCD_B1_Pin LCD_B2_Pin LCD_B3_Pin LCD_G4_Pin
                           LCD_G1_Pin LCD_G3_Pin LCD_G0_Pin LCD_G2_Pin
                           LCD_R7_Pin LCD_R5_Pin LCD_R6_Pin LCD_R4_Pin
                           LCD_R3_Pin LCD_R1_Pin LCD_R2_Pin */
  GPIO_InitStruct.Pin = LCD_B1_Pin|LCD_B2_Pin|LCD_B3_Pin|LCD_G4_Pin
                          |LCD_G1_Pin|LCD_G3_Pin|LCD_G0_Pin|LCD_G2_Pin
                          |LCD_R7_Pin|LCD_R5_Pin|LCD_R6_Pin|LCD_R4_Pin
                          |LCD_R3_Pin|LCD_R1_Pin|LCD_R2_Pin;
  GPIO_InitStruct.Mode = GPIO_MODE_AF_PP;
  GPIO_InitStruct.Pull = GPIO_NOPULL;
  GPIO_InitStruct.Speed = GPIO_SPEED_FREQ_LOW;
  GPIO_InitStruct.Alternate = GPIO_AF14_LTDC;
  HAL_GPIO_Init(GPIOJ, &GPIO_InitStruct);

  /*Configure GPIO pin : OTG_FS_VBUS_Pin */
  GPIO_InitStruct.Pin = OTG_FS_VBUS_Pin;
  GPIO_InitStruct.Mode = GPIO_MODE_INPUT;
  GPIO_InitStruct.Pull = GPIO_NOPULL;
  HAL_GPIO_Init(OTG_FS_VBUS_GPIO_Port, &GPIO_InitStruct);

  /*Configure GPIO pin : Audio_INT_Pin */
  GPIO_InitStruct.Pin = Audio_INT_Pin;
  GPIO_InitStruct.Mode = GPIO_MODE_EVT_RISING;
  GPIO_InitStruct.Pull = GPIO_NOPULL;
  HAL_GPIO_Init(Audio_INT_GPIO_Port, &GPIO_InitStruct);

  /*Configure GPIO pins : FMC_D2_Pin FMC_D3_Pin FMC_D1_Pin FMC_D15_Pin
                           FMC_D0_Pin FMC_D14_Pin FMC_D13_Pin */
  GPIO_InitStruct.Pin = FMC_D2_Pin|FMC_D3_Pin|FMC_D1_Pin|FMC_D15_Pin
                          |FMC_D0_Pin|FMC_D14_Pin|FMC_D13_Pin;
  GPIO_InitStruct.Mode = GPIO_MODE_AF_PP;
  GPIO_InitStruct.Pull = GPIO_NOPULL;
  GPIO_InitStruct.Speed = GPIO_SPEED_FREQ_VERY_HIGH;
  GPIO_InitStruct.Alternate = GPIO_AF12_FMC;
  HAL_GPIO_Init(GPIOD, &GPIO_InitStruct);

  /*Configure GPIO pins : OTG_FS_P_Pin OTG_FS_N_Pin OTG_FS_ID_Pin */
  GPIO_InitStruct.Pin = OTG_FS_P_Pin|OTG_FS_N_Pin|OTG_FS_ID_Pin;
  GPIO_InitStruct.Mode = GPIO_MODE_AF_PP;
  GPIO_InitStruct.Pull = GPIO_NOPULL;
  GPIO_InitStruct.Speed = GPIO_SPEED_FREQ_VERY_HIGH;
  GPIO_InitStruct.Alternate = GPIO_AF10_OTG_FS;
  HAL_GPIO_Init(GPIOA, &GPIO_InitStruct);

  /*Configure GPIO pins : SAI2_MCLKA_Pin SAI2_SCKA_Pin SAI2_FSA_Pin SAI2_SDA_Pin */
  GPIO_InitStruct.Pin = SAI2_MCLKA_Pin|SAI2_SCKA_Pin|SAI2_FSA_Pin|SAI2_SDA_Pin;
  GPIO_InitStruct.Mode = GPIO_MODE_AF_PP;
  GPIO_InitStruct.Pull = GPIO_NOPULL;
  GPIO_InitStruct.Speed = GPIO_SPEED_FREQ_LOW;
  GPIO_InitStruct.Alternate = GPIO_AF10_SAI2;
  HAL_GPIO_Init(GPIOI, &GPIO_InitStruct);

  /*Configure GPIO pins : LCD_DE_Pin LCD_B7_Pin LCD_B6_Pin LCD_B5_Pin
                           LCD_G6_Pin LCD_G7_Pin LCD_G5_Pin */
  GPIO_InitStruct.Pin = LCD_DE_Pin|LCD_B7_Pin|LCD_B6_Pin|LCD_B5_Pin
                          |LCD_G6_Pin|LCD_G7_Pin|LCD_G5_Pin;
  GPIO_InitStruct.Mode = GPIO_MODE_AF_PP;
  GPIO_InitStruct.Pull = GPIO_NOPULL;
  GPIO_InitStruct.Speed = GPIO_SPEED_FREQ_LOW;
  GPIO_InitStruct.Alternate = GPIO_AF14_LTDC;
  HAL_GPIO_Init(GPIOK, &GPIO_InitStruct);

  /*Configure GPIO pin : LCD_B4_Pin */
  GPIO_InitStruct.Pin = LCD_B4_Pin;
  GPIO_InitStruct.Mode = GPIO_MODE_AF_PP;
  GPIO_InitStruct.Pull = GPIO_NOPULL;
  GPIO_InitStruct.Speed = GPIO_SPEED_FREQ_LOW;
  GPIO_InitStruct.Alternate = GPIO_AF9_LTDC;
  HAL_GPIO_Init(LCD_B4_GPIO_Port, &GPIO_InitStruct);

  /*Configure GPIO pin : SAI2_SDB_Pin */
  GPIO_InitStruct.Pin = SAI2_SDB_Pin;
  GPIO_InitStruct.Mode = GPIO_MODE_AF_PP;
  GPIO_InitStruct.Pull = GPIO_NOPULL;
  GPIO_InitStruct.Speed = GPIO_SPEED_FREQ_LOW;
  GPIO_InitStruct.Alternate = GPIO_AF10_SAI2;
  HAL_GPIO_Init(SAI2_SDB_GPIO_Port, &GPIO_InitStruct);

  /*Configure GPIO pin : OTG_FS_PowerSwitchOn_Pin */
  GPIO_InitStruct.Pin = OTG_FS_PowerSwitchOn_Pin;
  GPIO_InitStruct.Mode = GPIO_MODE_OUTPUT_PP;
  GPIO_InitStruct.Pull = GPIO_NOPULL;
  GPIO_InitStruct.Speed = GPIO_SPEED_FREQ_LOW;
  HAL_GPIO_Init(OTG_FS_PowerSwitchOn_GPIO_Port, &GPIO_InitStruct);

  /*Configure GPIO pin : DCMI_D5_Pin */
  GPIO_InitStruct.Pin = DCMI_D5_Pin;
  GPIO_InitStruct.Mode = GPIO_MODE_AF_PP;
  GPIO_InitStruct.Pull = GPIO_NOPULL;
  GPIO_InitStruct.Speed = GPIO_SPEED_FREQ_LOW;
  GPIO_InitStruct.Alternate = GPIO_AF13_DCMI;
  HAL_GPIO_Init(DCMI_D5_GPIO_Port, &GPIO_InitStruct);

  /*Configure GPIO pins : Led_out_Pin Buzzer_out_Pin IndicatorBlue2_Pin */
  GPIO_InitStruct.Pin = Led_out_Pin|Buzzer_out_Pin|IndicatorBlue2_Pin;
  GPIO_InitStruct.Mode = GPIO_MODE_OUTPUT_PP;
  GPIO_InitStruct.Pull = GPIO_PULLDOWN;
  GPIO_InitStruct.Speed = GPIO_SPEED_FREQ_LOW;
  HAL_GPIO_Init(GPIOI, &GPIO_InitStruct);

  /*Configure GPIO pin : uSD_Detect_Pin */
  GPIO_InitStruct.Pin = uSD_Detect_Pin;
  GPIO_InitStruct.Mode = GPIO_MODE_INPUT;
  GPIO_InitStruct.Pull = GPIO_NOPULL;
  HAL_GPIO_Init(uSD_Detect_GPIO_Port, &GPIO_InitStruct);

  /*Configure GPIO pins : FMC_A0_Pin FMC_A1_Pin FMC_A2_Pin FMC_A3_Pin
                           FMC_A4_Pin FMC_A5_Pin FMC_A6_Pin FMC_A9_Pin
                           FMC_A7_Pin FMC_A8_Pin FMC_SDNRAS_Pin */
  GPIO_InitStruct.Pin = FMC_A0_Pin|FMC_A1_Pin|FMC_A2_Pin|FMC_A3_Pin
                          |FMC_A4_Pin|FMC_A5_Pin|FMC_A6_Pin|FMC_A9_Pin
                          |FMC_A7_Pin|FMC_A8_Pin|FMC_SDNRAS_Pin;
  GPIO_InitStruct.Mode = GPIO_MODE_AF_PP;
  GPIO_InitStruct.Pull = GPIO_NOPULL;
  GPIO_InitStruct.Speed = GPIO_SPEED_FREQ_VERY_HIGH;
  GPIO_InitStruct.Alternate = GPIO_AF12_FMC;
  HAL_GPIO_Init(GPIOF, &GPIO_InitStruct);

  /*Configure GPIO pins : LCD_HSYNC_Pin LCD_VSYNC_Pin LCD_R0_Pin LCD_CLK_Pin */
  GPIO_InitStruct.Pin = LCD_HSYNC_Pin|LCD_VSYNC_Pin|LCD_R0_Pin|LCD_CLK_Pin;
  GPIO_InitStruct.Mode = GPIO_MODE_AF_PP;
  GPIO_InitStruct.Pull = GPIO_NOPULL;
  GPIO_InitStruct.Speed = GPIO_SPEED_FREQ_LOW;
  GPIO_InitStruct.Alternate = GPIO_AF14_LTDC;
  HAL_GPIO_Init(GPIOI, &GPIO_InitStruct);

  /*Configure GPIO pin : LCD_BL_CTRL_Pin */
  GPIO_InitStruct.Pin = LCD_BL_CTRL_Pin;
  GPIO_InitStruct.Mode = GPIO_MODE_OUTPUT_PP;
  GPIO_InitStruct.Pull = GPIO_NOPULL;
  GPIO_InitStruct.Speed = GPIO_SPEED_FREQ_LOW;
  HAL_GPIO_Init(LCD_BL_CTRL_GPIO_Port, &GPIO_InitStruct);

  /*Configure GPIO pin : DCMI_VSYNC_Pin */
  GPIO_InitStruct.Pin = DCMI_VSYNC_Pin;
  GPIO_InitStruct.Mode = GPIO_MODE_AF_PP;
  GPIO_InitStruct.Pull = GPIO_NOPULL;
  GPIO_InitStruct.Speed = GPIO_SPEED_FREQ_LOW;
  GPIO_InitStruct.Alternate = GPIO_AF13_DCMI;
  HAL_GPIO_Init(DCMI_VSYNC_GPIO_Port, &GPIO_InitStruct);

  /*Configure GPIO pin : OTG_FS_OverCurrent_Pin */
  GPIO_InitStruct.Pin = OTG_FS_OverCurrent_Pin;
  GPIO_InitStruct.Mode = GPIO_MODE_INPUT;
  GPIO_InitStruct.Pull = GPIO_NOPULL;
  HAL_GPIO_Init(OTG_FS_OverCurrent_GPIO_Port, &GPIO_InitStruct);

  /*Configure GPIO pin : SDMMC_CMD_Pin */
  GPIO_InitStruct.Pin = SDMMC_CMD_Pin;
  GPIO_InitStruct.Mode = GPIO_MODE_AF_PP;
  GPIO_InitStruct.Pull = GPIO_NOPULL;
  GPIO_InitStruct.Speed = GPIO_SPEED_FREQ_VERY_HIGH;
  GPIO_InitStruct.Alternate = GPIO_AF12_SDMMC1;
  HAL_GPIO_Init(SDMMC_CMD_GPIO_Port, &GPIO_InitStruct);

  /*Configure GPIO pins : TP3_Pin NC2_Pin */
  GPIO_InitStruct.Pin = TP3_Pin|NC2_Pin;
  GPIO_InitStruct.Mode = GPIO_MODE_INPUT;
  GPIO_InitStruct.Pull = GPIO_NOPULL;
  HAL_GPIO_Init(GPIOH, &GPIO_InitStruct);

  /*Configure GPIO pin : ARDUINO_SCK_D13_Pin */
  GPIO_InitStruct.Pin = ARDUINO_SCK_D13_Pin;
  GPIO_InitStruct.Mode = GPIO_MODE_AF_PP;
  GPIO_InitStruct.Pull = GPIO_NOPULL;
  GPIO_InitStruct.Speed = GPIO_SPEED_FREQ_LOW;
  GPIO_InitStruct.Alternate = GPIO_AF5_SPI2;
  HAL_GPIO_Init(ARDUINO_SCK_D13_GPIO_Port, &GPIO_InitStruct);

  /*Configure GPIO pin : LCD_DISP_Pin */
  GPIO_InitStruct.Pin = LCD_DISP_Pin;
  GPIO_InitStruct.Mode = GPIO_MODE_OUTPUT_PP;
  GPIO_InitStruct.Pull = GPIO_NOPULL;
  GPIO_InitStruct.Speed = GPIO_SPEED_FREQ_LOW;
  HAL_GPIO_Init(LCD_DISP_GPIO_Port, &GPIO_InitStruct);

  /*Configure GPIO pin : DCMI_PWR_EN_Pin */
  GPIO_InitStruct.Pin = DCMI_PWR_EN_Pin;
  GPIO_InitStruct.Mode = GPIO_MODE_OUTPUT_PP;
  GPIO_InitStruct.Pull = GPIO_NOPULL;
  GPIO_InitStruct.Speed = GPIO_SPEED_FREQ_LOW;
  HAL_GPIO_Init(DCMI_PWR_EN_GPIO_Port, &GPIO_InitStruct);

  /*Configure GPIO pins : DCMI_D4_Pin DCMI_D3_Pin DCMI_D0_Pin DCMI_D2_Pin
                           DCMI_D1_Pin */
  GPIO_InitStruct.Pin = DCMI_D4_Pin|DCMI_D3_Pin|DCMI_D0_Pin|DCMI_D2_Pin
                          |DCMI_D1_Pin;
  GPIO_InitStruct.Mode = GPIO_MODE_AF_PP;
  GPIO_InitStruct.Pull = GPIO_NOPULL;
  GPIO_InitStruct.Speed = GPIO_SPEED_FREQ_LOW;
  GPIO_InitStruct.Alternate = GPIO_AF13_DCMI;
  HAL_GPIO_Init(GPIOH, &GPIO_InitStruct);

  /*Configure GPIO pin : Btn_pin_Pin */
  GPIO_InitStruct.Pin = Btn_pin_Pin;
  GPIO_InitStruct.Mode = GPIO_MODE_INPUT;
  GPIO_InitStruct.Pull = GPIO_PULLDOWN;
  HAL_GPIO_Init(Btn_pin_GPIO_Port, &GPIO_InitStruct);

  /*Configure GPIO pin : ARDUINO_PWM_D10_Pin */
  GPIO_InitStruct.Pin = ARDUINO_PWM_D10_Pin;
  GPIO_InitStruct.Mode = GPIO_MODE_AF_PP;
  GPIO_InitStruct.Pull = GPIO_NOPULL;
  GPIO_InitStruct.Speed = GPIO_SPEED_FREQ_LOW;
  GPIO_InitStruct.Alternate = GPIO_AF1_TIM1;
  HAL_GPIO_Init(ARDUINO_PWM_D10_GPIO_Port, &GPIO_InitStruct);

  /*Configure GPIO pin : LCD_INT_Pin */
  GPIO_InitStruct.Pin = LCD_INT_Pin;
  GPIO_InitStruct.Mode = GPIO_MODE_EVT_RISING;
  GPIO_InitStruct.Pull = GPIO_NOPULL;
  HAL_GPIO_Init(LCD_INT_GPIO_Port, &GPIO_InitStruct);

  /*Configure GPIO pin : ARDUINO_RX_D0_Pin */
  GPIO_InitStruct.Pin = ARDUINO_RX_D0_Pin;
  GPIO_InitStruct.Mode = GPIO_MODE_AF_PP;
  GPIO_InitStruct.Pull = GPIO_NOPULL;
  GPIO_InitStruct.Speed = GPIO_SPEED_FREQ_VERY_HIGH;
  GPIO_InitStruct.Alternate = GPIO_AF8_USART6;
  HAL_GPIO_Init(ARDUINO_RX_D0_GPIO_Port, &GPIO_InitStruct);

  /*Configure GPIO pin : IndicatorGreen_Pin */
  GPIO_InitStruct.Pin = IndicatorGreen_Pin;
  GPIO_InitStruct.Mode = GPIO_MODE_OUTPUT_PP;
  GPIO_InitStruct.Pull = GPIO_PULLDOWN;
  GPIO_InitStruct.Speed = GPIO_SPEED_FREQ_LOW;
  HAL_GPIO_Init(IndicatorGreen_GPIO_Port, &GPIO_InitStruct);

  /*Configure GPIO pins : FMC_SDNME_Pin FMC_SDNE0_Pin */
  GPIO_InitStruct.Pin = FMC_SDNME_Pin|FMC_SDNE0_Pin;
  GPIO_InitStruct.Mode = GPIO_MODE_AF_PP;
  GPIO_InitStruct.Pull = GPIO_NOPULL;
  GPIO_InitStruct.Speed = GPIO_SPEED_FREQ_VERY_HIGH;
  GPIO_InitStruct.Alternate = GPIO_AF12_FMC;
  HAL_GPIO_Init(GPIOH, &GPIO_InitStruct);

  /*Configure GPIO pins : IndicatorBlue1_Pin IndicatorYellow1_Pin */
  GPIO_InitStruct.Pin = IndicatorBlue1_Pin|IndicatorYellow1_Pin;
  GPIO_InitStruct.Mode = GPIO_MODE_OUTPUT_PP;
  GPIO_InitStruct.Pull = GPIO_PULLDOWN;
  GPIO_InitStruct.Speed = GPIO_SPEED_FREQ_LOW;
  HAL_GPIO_Init(GPIOG, &GPIO_InitStruct);

  /*Configure GPIO pin : FMC_SDCKE0_Pin */
  GPIO_InitStruct.Pin = FMC_SDCKE0_Pin;
  GPIO_InitStruct.Mode = GPIO_MODE_AF_PP;
  GPIO_InitStruct.Pull = GPIO_NOPULL;
  GPIO_InitStruct.Speed = GPIO_SPEED_FREQ_VERY_HIGH;
  GPIO_InitStruct.Alternate = GPIO_AF12_FMC;
  HAL_GPIO_Init(FMC_SDCKE0_GPIO_Port, &GPIO_InitStruct);

  /*Configure GPIO pins : RMII_MDC_Pin RMII_RXD0_Pin RMII_RXD1_Pin */
  GPIO_InitStruct.Pin = RMII_MDC_Pin|RMII_RXD0_Pin|RMII_RXD1_Pin;
  GPIO_InitStruct.Mode = GPIO_MODE_AF_PP;
  GPIO_InitStruct.Pull = GPIO_NOPULL;
  GPIO_InitStruct.Speed = GPIO_SPEED_FREQ_VERY_HIGH;
  GPIO_InitStruct.Alternate = GPIO_AF11_ETH;
  HAL_GPIO_Init(GPIOC, &GPIO_InitStruct);

  /*Configure GPIO pin : PB2 */
  GPIO_InitStruct.Pin = GPIO_PIN_2;
  GPIO_InitStruct.Mode = GPIO_MODE_AF_PP;
  GPIO_InitStruct.Pull = GPIO_NOPULL;
  GPIO_InitStruct.Speed = GPIO_SPEED_FREQ_VERY_HIGH;
  GPIO_InitStruct.Alternate = GPIO_AF9_QUADSPI;
  HAL_GPIO_Init(GPIOB, &GPIO_InitStruct);

  /*Configure GPIO pins : QSPI_D1_Pin QSPI_D3_Pin QSPI_D0_Pin */
  GPIO_InitStruct.Pin = QSPI_D1_Pin|QSPI_D3_Pin|QSPI_D0_Pin;
  GPIO_InitStruct.Mode = GPIO_MODE_AF_PP;
  GPIO_InitStruct.Pull = GPIO_NOPULL;
  GPIO_InitStruct.Speed = GPIO_SPEED_FREQ_VERY_HIGH;
  GPIO_InitStruct.Alternate = GPIO_AF9_QUADSPI;
  HAL_GPIO_Init(GPIOD, &GPIO_InitStruct);

  /*Configure GPIO pin : EXT_RST_Pin */
  GPIO_InitStruct.Pin = EXT_RST_Pin;
  GPIO_InitStruct.Mode = GPIO_MODE_OUTPUT_PP;
  GPIO_InitStruct.Pull = GPIO_NOPULL;
  GPIO_InitStruct.Speed = GPIO_SPEED_FREQ_LOW;
  HAL_GPIO_Init(EXT_RST_GPIO_Port, &GPIO_InitStruct);

  /*Configure GPIO pin : RMII_RXER_Pin */
  GPIO_InitStruct.Pin = RMII_RXER_Pin;
  GPIO_InitStruct.Mode = GPIO_MODE_INPUT;
  GPIO_InitStruct.Pull = GPIO_NOPULL;
  HAL_GPIO_Init(RMII_RXER_GPIO_Port, &GPIO_InitStruct);

  /*Configure GPIO pins : RMII_REF_CLK_Pin RMII_MDIO_Pin RMII_CRS_DV_Pin */
  GPIO_InitStruct.Pin = RMII_REF_CLK_Pin|RMII_MDIO_Pin|RMII_CRS_DV_Pin;
  GPIO_InitStruct.Mode = GPIO_MODE_AF_PP;
  GPIO_InitStruct.Pull = GPIO_NOPULL;
  GPIO_InitStruct.Speed = GPIO_SPEED_FREQ_VERY_HIGH;
  GPIO_InitStruct.Alternate = GPIO_AF11_ETH;
  HAL_GPIO_Init(GPIOA, &GPIO_InitStruct);

  /*Configure GPIO pins : DCMI_HSYNC_Pin PA6 */
  GPIO_InitStruct.Pin = DCMI_HSYNC_Pin|GPIO_PIN_6;
  GPIO_InitStruct.Mode = GPIO_MODE_AF_PP;
  GPIO_InitStruct.Pull = GPIO_NOPULL;
  GPIO_InitStruct.Speed = GPIO_SPEED_FREQ_LOW;
  GPIO_InitStruct.Alternate = GPIO_AF13_DCMI;
  HAL_GPIO_Init(GPIOA, &GPIO_InitStruct);

  /*Configure GPIO pins : LCD_SCL_Pin LCD_SDA_Pin */
  GPIO_InitStruct.Pin = LCD_SCL_Pin|LCD_SDA_Pin;
  GPIO_InitStruct.Mode = GPIO_MODE_AF_OD;
  GPIO_InitStruct.Pull = GPIO_PULLUP;
  GPIO_InitStruct.Speed = GPIO_SPEED_FREQ_VERY_HIGH;
  GPIO_InitStruct.Alternate = GPIO_AF4_I2C3;
  HAL_GPIO_Init(GPIOH, &GPIO_InitStruct);

  /*Configure GPIO pin : ULPI_D3_Pin */
  GPIO_InitStruct.Pin = ULPI_D3_Pin;
  GPIO_InitStruct.Mode = GPIO_MODE_AF_PP;
  GPIO_InitStruct.Pull = GPIO_NOPULL;
  GPIO_InitStruct.Speed = GPIO_SPEED_FREQ_VERY_HIGH;
  GPIO_InitStruct.Alternate = GPIO_AF10_OTG_HS;
  HAL_GPIO_Init(ULPI_D3_GPIO_Port, &GPIO_InitStruct);

  /*Configure GPIO pin : IndicatorBlue3_Pin */
  GPIO_InitStruct.Pin = IndicatorBlue3_Pin;
  GPIO_InitStruct.Mode = GPIO_MODE_OUTPUT_PP;
  GPIO_InitStruct.Pull = GPIO_PULLDOWN;
  GPIO_InitStruct.Speed = GPIO_SPEED_FREQ_LOW;
  HAL_GPIO_Init(IndicatorBlue3_GPIO_Port, &GPIO_InitStruct);

  /*Configure GPIO pins : ARDUINO_MISO_D12_Pin ARDUINO_MOSI_PWM_D11_Pin */
  GPIO_InitStruct.Pin = ARDUINO_MISO_D12_Pin|ARDUINO_MOSI_PWM_D11_Pin;
  GPIO_InitStruct.Mode = GPIO_MODE_AF_PP;
  GPIO_InitStruct.Pull = GPIO_NOPULL;
  GPIO_InitStruct.Speed = GPIO_SPEED_FREQ_LOW;
  GPIO_InitStruct.Alternate = GPIO_AF5_SPI2;
  HAL_GPIO_Init(GPIOB, &GPIO_InitStruct);

}

void StartMainTask(void *argument)
{
  /* USER CODE BEGIN 5 */
	//Setup code
	ProgramStateFSM progStateLocal;
	float PPMValue;
	bool sentAlarmMSG = false; // flag to transmit alarm msg only once
	bool meassuring = false;
	uint16_t delay_main_task_time = 5;

  /* Infinite loop */
  for(;;)
  {
	  osMutexAcquire(RegimeMutexHandle, osWaitForever);
	  progStateLocal = progState;
	  osMutexRelease(RegimeMutexHandle);

	  PPMValue = ReadGasSensor();

	  switch(progStateLocal)
	  {
	  	  case P_IDLE_START:

	  		  osMutexAcquire(UARTMutexHandle, osWaitForever);

	  		  HelpSendUART(len_of_array, cmdStrings);
	  		  UART_TransmitString(IdleMSG);
	  		  osMutexRelease(UARTMutexHandle);

	  		  osMutexAcquire(RegimeMutexHandle, osWaitForever);
	  		  progState = P_IDLE;
	  		  osMutexRelease(RegimeMutexHandle);

	  		  osMutexAcquire(LED_FSM_MutexHandle, osWaitForever);
	  		  ledState = LED_OFF;
	  		  osMutexRelease(LED_FSM_MutexHandle);

	  		  osMutexAcquire(SystemWorkStateMutexHandle, osWaitForever);
	  		  progChangeState = PC_IDLE;
	  		  osMutexRelease(SystemWorkStateMutexHandle);

	  		  meassuring = false;
	  		  SetIndicatorLEDs(0); // resets the indicator

		  break;

	  	  case P_IDLE:

	  		  //System waits for configuration
	  		  meassuring = false;
	  		  delay_main_task_time = 5;

		  break;

	  	  case P_WORK_S1:

	  		  meassuring = true;

	  		  osMutexAcquire(UARTMutexHandle, osWaitForever);
	  		  UART_TransmitString(PPM_MSG);
	  		  UART_TransmitFloat(PPMValue);
	  		  osMutexRelease(UARTMutexHandle);
	  		  delay_main_task_time = 1000;

	  		  osMutexAcquire(SystemWorkStateMutexHandle, osWaitForever);
	  		  if(progChangeState == PC_IDLE)
	  		  {
		  		  progChangeState = PC_WORK_START;
	  		  }
	  	      osMutexRelease(SystemWorkStateMutexHandle);

		  break;

	  	  case P_WORK_S3:

	  		  meassuring = true;

	  		  osMutexAcquire(UARTMutexHandle, osWaitForever);
	  		  UART_TransmitString(PPM_MSG);
	  		  UART_TransmitFloat(PPMValue);
	  		  osMutexRelease(UARTMutexHandle);

	  		  osMutexAcquire(SystemWorkStateMutexHandle, osWaitForever);
	  		  if(progChangeState == PC_IDLE)
	  		  {
		  		  progChangeState = PC_WORK_START;
	  		  }
	  	      osMutexRelease(SystemWorkStateMutexHandle);
	  	      delay_main_task_time = 3000;
		  break;

	  	  case P_WORK_S5:

	  		  meassuring = true;

	  		  osMutexAcquire(UARTMutexHandle, osWaitForever);
	  		  UART_TransmitString(PPM_MSG);
	  		  UART_TransmitFloat(PPMValue);
	  		  osMutexRelease(UARTMutexHandle);

	  		  osMutexAcquire(SystemWorkStateMutexHandle, osWaitForever);
	  		  if(progChangeState == PC_IDLE)
	  		  {
		  		  progChangeState = PC_WORK_START;
	  		  }
	  	      osMutexRelease(SystemWorkStateMutexHandle);

	  	      delay_main_task_time = 5000;

		  break;
	  }

	  osMutexAcquire(SystemWorkStateMutexHandle, osWaitForever);
	  if(progChangeState == PC_WORK_START)
	  {
		  progChangeState = PC_WORK;
	  }
	  osMutexRelease(SystemWorkStateMutexHandle);

	  //Take action
	  //Setting the indicator system
	  if(meassuring == true)
	  {
		  SetIndicatorLEDs(PPMValue);
	  }

	  //Check for contamination
	  if(meassuring == true)
	  {
		  if(PPMValue > DangerousPPM)
		  {
			  osMutexAcquire(UARTMutexHandle, osWaitForever);
			  UART_TransmitString(AlertMSG);
			  osMutexRelease(UARTMutexHandle);

			  osMutexAcquire(LED_Blink_MutexHandle, osWaitForever);
			  quality_status = false;
			  osMutexRelease(LED_Blink_MutexHandle);

			  sentAlarmMSG = true;
			  AlarmON();
		  }
		  else
		  {
			  osMutexAcquire(LED_Blink_MutexHandle, osWaitForever);
			  quality_status = true;
			  osMutexRelease(LED_Blink_MutexHandle);

			  AlarmOFF();
			  if(sentAlarmMSG == true)
			  {
				  osMutexAcquire(UARTMutexHandle, osWaitForever);
				  UART_TransmitString(RoomClearedMSG);
				  osMutexRelease(UARTMutexHandle);

				  sentAlarmMSG = false; // to be avaliable for next time danger happens
			  }
		  }
	  }
	  osDelay(delay_main_task_time);
  }

  /* USER CODE END 5 */
}

void StartTerminalTask(void *argument)
{
  /* USER CODE BEGIN StartTerminalTask */
	//Setup code
	ProgramStateFSM progStateLocal;
	UART_commandsFSM uartCmdState;
	uint16_t CommandIndex;
	bool CommandStatus;
	float LocalPPM;
  /* Infinite loop */
  for(;;)
  {
	  if(IsTransferComplete() == true)
	  {
		  CommandStatus = StringCompareFromUART(GetRxBuffer(), cmdStrings, len_of_array, &CommandIndex);
		  if(CommandStatus == false)
		  {
			  UART_TransmitString(ErrorMSG);
			  ClearRxBuffer();

			  osMutexAcquire(UARTMutexHandle, osWaitForever);
			  HelpSendUART(len_of_array, cmdStrings);
			  osMutexRelease(UARTMutexHandle);

			  progStateLocal = P_IDLE;
		  }
		  else
		  {
			  ClearRxBuffer();
				uartCmdState = CommandIndex;

				switch(uartCmdState)
				{
					case cmd_0:

						progStateLocal = P_IDLE_START;

						break;

					case cmd_1:

						progStateLocal = P_WORK_S1;
						UART_TransmitString(S1WorkStateMSG);

						break;

					case cmd_2:

						progStateLocal = P_WORK_S3;
						UART_TransmitString(S3WorkStateMSG);

						break;

					case cmd_3:

						progStateLocal = P_WORK_S5;
						UART_TransmitString(S5WorkStateMSG);

						break;

					case cmd_4:

						LocalPPM = ReadGasSensor();

						break;

					case cmd_5:

						UART_TransmitString(PPM_MSG);
						UART_TransmitFloat(LocalPPM);

						break;

					case cmd_6:

						UART_TransmitString(FAN_ON);
						progStateLocal = P_IDLE;

						break;

					case cmd_7:

						UART_TransmitString(FAN_OFF);
						progStateLocal = P_IDLE;

						break;

					case cmd_8:

						AlarmON();
						progStateLocal = P_IDLE;

						break;

					case cmd_9:

						AlarmOFF();
						progStateLocal = P_IDLE;

						break;

					case cmd_10:

						LED_Drive(true);
						progStateLocal = P_IDLE;

						break;

					case cmd_11:

						LED_Drive(false);
						progStateLocal = P_IDLE;

						break;

					case cmd_12:

						SetIndicatorLEDsNum(0);
						progStateLocal = P_IDLE;

						break;

					case cmd_13:

						SetIndicatorLEDsNum(1);
						progStateLocal = P_IDLE;

						break;

					case cmd_14:

						SetIndicatorLEDsNum(2);
						progStateLocal = P_IDLE;

						break;

					case cmd_15:

						SetIndicatorLEDsNum(3);
						progStateLocal = P_IDLE;

						break;

					case cmd_16:

						SetIndicatorLEDsNum(4);
						progStateLocal = P_IDLE;

						break;

					case cmd_17:

						SetIndicatorLEDsNum(5);
						progStateLocal = P_IDLE;

						break;

					case cmd_18:

						SetIndicatorLEDsNum(6);
						progStateLocal = P_IDLE;

						break;

					case cmd_19:

						HelpSendUART(len_of_array, cmdStrings);
						progStateLocal = P_IDLE;

						break;

					case cmd_20:
						// reserved

						break;
				}

				osMutexAcquire(RegimeMutexHandle, osWaitForever);
				progState = progStateLocal;
				osMutexRelease(RegimeMutexHandle);
		  }
	  }

    osDelay(10);
  }
  /* USER CODE END StartTerminalTask */
}

void StartButtonTask(void *argument)
{
  /* USER CODE BEGIN StartButtonTask */
	//Setup code
	bool read_button_flag = true;
	bool press_button_flag = false;

  /* Infinite loop */
  for(;;)
  {
	press_button_flag = ReadSignal(&read_button_flag);
    if(press_button_flag == true)
    {
    	osTimerStart(ButtonTimerHandle, 3000);

    	osMutexAcquire(ButtonCountMutexHandle, osWaitForever);
    	button_press_counter++;
    	osMutexRelease(ButtonCountMutexHandle);

    	press_button_flag = false;
    }
    osDelay(5);
  }
  /* USER CODE END StartButtonTask */
}

void StartSingleLEDTask(void *argument)
{
  /* USER CODE BEGIN StartSingleLEDTask */
	//Setup code
	LED_StatusFSM ledStateLocal;
	bool quality_status_local;
	ProgramStateFSM progStateLocal;
	bool local_task_enable = false;

	uint16_t delay_time = 10;
  /* Infinite loop */
  for(;;)
  {
	  osMutexAcquire(LED_Blink_MutexHandle, osWaitForever);
	  quality_status_local = quality_status;
	  osMutexRelease(LED_Blink_MutexHandle);

	  osMutexAcquire(LED_FSM_MutexHandle, osWaitForever);
	  ledStateLocal = ledState;
	  osMutexRelease(LED_FSM_MutexHandle);

	  osMutexAcquire(RegimeMutexHandle, osWaitForever);
	  progStateLocal = progState;
	  osMutexRelease(RegimeMutexHandle);

	if((progStateLocal != P_IDLE_START) && (progStateLocal != P_IDLE))
	{
		//============ Checking does system first time in work state after idle state ============//
		osMutexAcquire(SystemWorkStateMutexHandle, osWaitForever);
		if(progChangeState == PC_WORK)
		{
			local_task_enable = true;
			progChangeState = PC_WORK_CHECK;
		}
		else
		{
			local_task_enable = false;
		}
		osMutexRelease(SystemWorkStateMutexHandle);
		//========= END  Checking does system first time in work state after idle state =========//

		//============ Update logic state ===================//

		if(local_task_enable == true)
		{
			if(quality_status_local == true)
			{
				ledStateLocal = LED_ON_CORRECT;
			}
			else if(quality_status_local == false)
			{
				ledStateLocal = LED_ON_INCORRECT;
			}
			local_task_enable = false;
		}
		else
		{
			switch(ledStateLocal)
			{
				case LED_OFF:
					LED_Drive(false);
					delay_time = 3000;
					if(quality_status_local == true)
					{
						ledStateLocal = LED_ON_CORRECT;
					}
					else
					{
						ledStateLocal = LED_ON_INCORRECT;
					}

					break;

				case LED_ON_CORRECT:
					LED_Drive(true);
					delay_time = 2000;
					ledStateLocal = LED_OFF;

					break;

				case LED_ON_INCORRECT:

					LED_Drive(true);
					delay_time = 100;
					ledStateLocal = LED_OFF;

					break;
			}
		}

		//========== Keep LED state for delay_time ===========//
		osMutexAcquire(LED_FSM_MutexHandle, osWaitForever);
		ledState = ledStateLocal;
		osMutexRelease(LED_FSM_MutexHandle);
		//========== END Keep LED state for delay_time ===========//

	}
	osDelay(delay_time);
  }
  /* USER CODE END StartSingleLEDTask */
}

/* ButtonTimerCallback function */
void ButtonTimerCallback(void *argument)
{
  /* USER CODE BEGIN ButtonTimerCallback */
	ProgramStateFSM progStateLocal;
	uint8_t ButtonCountLocal;

	osMutexAcquire(ButtonCountMutexHandle, osWaitForever);
	ButtonCountLocal = button_press_counter;
	osMutexRelease(ButtonCountMutexHandle);

	switch(ButtonCountLocal)
	{
		case 0:

			progStateLocal = P_IDLE_START;

			break;

		case 1:

			progStateLocal = P_WORK_S1;
			UART_TransmitString(S1WorkStateMSG);

			break;

		case 2:

			progStateLocal = P_WORK_S3;
			UART_TransmitString(S3WorkStateMSG);

			break;

		case 3:

			progStateLocal = P_WORK_S5;
			UART_TransmitString(S5WorkStateMSG);

			break;

		case 4:

			// Not specified

			break;

		case 5:

			progStateLocal = P_IDLE_START;

			break;

	}

	osMutexAcquire(ButtonCountMutexHandle, osWaitForever);
	button_press_counter = 0;
	osMutexRelease(ButtonCountMutexHandle);

    osMutexAcquire(RegimeMutexHandle, osWaitForever);
    progState = progStateLocal;
	osMutexRelease(RegimeMutexHandle);

   //osTimerStop(ButtonTimerHandle);
  /* USER CODE END ButtonTimerCallback */
}

void HAL_TIM_PeriodElapsedCallback(TIM_HandleTypeDef *htim)
{
  if (htim->Instance == TIM14) {
    HAL_IncTick();
  }
}

void Error_Handler(void)
{
  __disable_irq();
  while (1)
  {
  }
}
